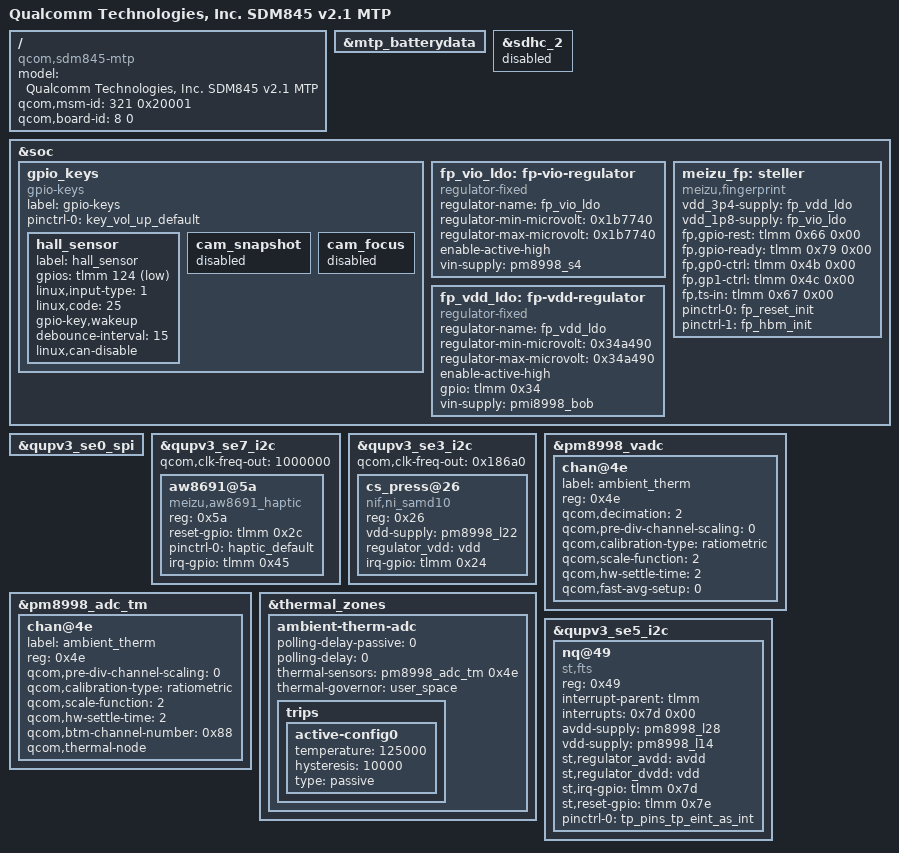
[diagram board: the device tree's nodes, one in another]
/*
 * Copyright (C) 2023 transaero21 <transaero21@elseboot.ru>
 *
 * SPDX-License-Identifier: GPL-2.0
 */

#include <dt-bindings/clock/qcom,gcc-sdm845.h>
#include <dt-bindings/clock/qcom,camcc-sdm845.h>
#include <dt-bindings/clock/qcom,dispcc-sdm845.h>
#include <dt-bindings/clock/qcom,rpmh.h>
#include <dt-bindings/interrupt-controller/arm-gic.h>

#include "../sdm845-mtp.dtsi"

#include "sdm845-audio-overlay.dtsi"
#include "sdm845-display-overlay.dtsi"
#include "sdm845-camera-overlay.dtsi"
#include "sdm845-pmic-overlay.dtsi"
#include "sdm845-usb-overlay.dtsi"

/ {
	model = "Qualcomm Technologies, Inc. SDM845 v2.1 MTP";
	compatible = "qcom,sdm845-mtp", "qcom,sdm845", "qcom,mtp";
	qcom,msm-id = <321 0x20001>;
	qcom,board-id = <8 0>;
};

&mtp_batterydata {
	/delete-node/ qcom,itech_3000mah;
	/delete-node/ qcom,ascent_3450mah;
	/delete-node/ qcom,demo-6000mah;
};

&sdhc_2 {
	status = "disabled";
};

&soc {
	gpio_keys {
		compatible = "gpio-keys";
		label = "gpio-keys";

		pinctrl-names = "default";
		pinctrl-0 = <&key_vol_up_default>;

		hall_sensor {
			label = "hall_sensor";
			gpios = <&tlmm 124 GPIO_ACTIVE_LOW>;
			linux,input-type = <1>;
			linux,code = <25>;
			gpio-key,wakeup;
			debounce-interval = <15>;
			linux,can-disable;
		};

		cam_snapshot {
			status = "disabled";
		};

		cam_focus {
			status = "disabled";
		};
	};
};

&qupv3_se0_spi {
	status = "ok";
};

&qupv3_se7_i2c {
	status = "ok";
	qcom,clk-freq-out = <1000000>;

	aw8691@5a {
		compatible = "meizu,aw8691_haptic";
		reg = <0x5a>;
		reset-gpio = <&tlmm 0x2c 0x00>;
		pinctrl-names = "default";
		pinctrl-0 = <&haptic_default>;
		irq-gpio = <&tlmm 0x45 0x00>;
	};
};

&qupv3_se3_i2c {
	qcom,clk-freq-out = <0x186a0>;

	cs_press@26 {
		compatible = "nif,ni_samd10";
		reg = <0x26>;
		vdd-supply = <&pm8998_l22>;
		regulator_vdd = "vdd";
		irq-gpio = <&tlmm 0x24 0x00>;
		status = "okay";
	};
};

&pm8998_vadc {
	chan@4e {
		label = "ambient_therm";
		reg = <0x4e>;
		qcom,decimation = <2>;
		qcom,pre-div-channel-scaling = <0>;
		qcom,calibration-type = "ratiometric";
		qcom,scale-function = <2>;
		qcom,hw-settle-time = <2>;
		qcom,fast-avg-setup = <0>;
	};
};

&pm8998_adc_tm {
	chan@4e {
		label = "ambient_therm";
		reg = <0x4e>;
		qcom,pre-div-channel-scaling = <0>;
		qcom,calibration-type = "ratiometric";
		qcom,scale-function = <2>;
		qcom,hw-settle-time = <2>;
		qcom,btm-channel-number = <0x88>;
		qcom,thermal-node;
	};
};

&thermal_zones {
	ambient-therm-adc {
		polling-delay-passive = <0>;
		polling-delay = <0>;
		thermal-sensors = <&pm8998_adc_tm 0x4e>;
		thermal-governor = "user_space";

		trips {
			active-config0 {
				temperature = <125000>;
				hysteresis = <10000>;
				type = "passive";
			};
		};
	};
};

&qupv3_se5_i2c {
	status = "ok";

	nq@49 {
		compatible = "st,fts";
		reg = <0x49>;
		interrupt-parent = <&tlmm>;
		interrupts = <0x7d 0x00>;
		avdd-supply = <&pm8998_l28>;
		vdd-supply = <&pm8998_l14>;
		st,regulator_avdd = "avdd";
		st,regulator_dvdd = "vdd";
		st,irq-gpio = <&tlmm 0x7d 0x00>;
		st,reset-gpio = <&tlmm 0x7e 0x00>;
		pinctrl-names = "tp_int";
		pinctrl-0 = <&tp_pins_tp_eint_as_int>;
	};
};

&soc {
	fp_vio_ldo: fp-vio-regulator {
		compatible = "regulator-fixed";
		regulator-name = "fp_vio_ldo";
		regulator-min-microvolt = <0x1b7740>;
		regulator-max-microvolt = <0x1b7740>;
		enable-active-high;
		vin-supply = <&pm8998_s4>;
	};

	fp_vdd_ldo: fp-vdd-regulator {
		compatible = "regulator-fixed";
		regulator-name = "fp_vdd_ldo";
		regulator-min-microvolt = <0x34a490>;
		regulator-max-microvolt = <0x34a490>;
		enable-active-high;
		gpio = <&tlmm 0x34 0x00>;
		vin-supply = <&pmi8998_bob>;
	};

	meizu_fp: steller {
		status = "okay";
		compatible = "meizu,fingerprint";
		vdd_3p4-supply = <&fp_vdd_ldo>;
		vdd_1p8-supply = <&fp_vio_ldo>;
		fp,gpio-rest = <&tlmm 0x66 0x00>;
		fp,gpio-ready = <&tlmm 0x79 0x00>;
		fp,gp0-ctrl = <&tlmm 0x4b 0x00>;
		fp,gp1-ctrl = <&tlmm 0x4c 0x00>;
		fp,ts-in = <&tlmm 0x67 0x00>;
		pinctrl-names = "fp_reset_init", "fp_hbm_init";
		pinctrl-0 = <&fp_reset_init>;
		pinctrl-1 = <&fp_hbm_init>;
	};
};
